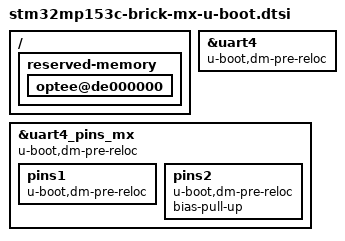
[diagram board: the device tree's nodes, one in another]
/* SPDX-License-Identifier: GPL-2.0+ OR BSD-3-Clause*/
/*
 * Copyright (C) 2022, STMicroelectronics - All Rights Reserved
 * Author: STM32CubeMX code generation for STMicroelectronics.
 */

/* For more information on Device Tree configuration, please refer to
 * https://wiki.st.com/stm32mpu/wiki/Category:Device_tree_configuration
 */

#include "stm32mp15-u-boot.dtsi"

/* USER CODE BEGIN includes */
/* USER CODE END includes */

/ {

	/* USER CODE BEGIN root */
	reserved-memory {
		u-boot,dm-spl;

		optee@de000000 {
			u-boot,dm-spl;
		};
	};
	/* USER CODE END root */

}; /*root*/

/* USER CODE BEGIN addons */
&uart4 {
	u-boot,dm-pre-reloc;
};

&uart4_pins_mx {
	u-boot,dm-pre-reloc;
	pins1 {
		u-boot,dm-pre-reloc;
	};
	pins2 {
		u-boot,dm-pre-reloc;
		/* pull-up on rx to avoid floating level */
		bias-pull-up;
	};
};
/* USER CODE END addons */

